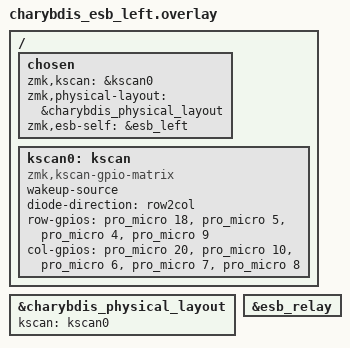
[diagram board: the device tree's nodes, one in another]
#include "charybdis_matrix.dtsi"
#include "charybdis_esb_addr.dtsi"

/ {
    chosen {
        zmk,kscan = &kscan0;
        zmk,physical-layout = &charybdis_physical_layout;
        zmk,esb-self = &esb_left;
    };

    kscan0: kscan {
        compatible = "zmk,kscan-gpio-matrix";
        wakeup-source;
        diode-direction = "row2col";
        row-gpios
            = <&pro_micro 18 GPIO_ACTIVE_HIGH>
            , <&pro_micro 5 GPIO_ACTIVE_HIGH>
            , <&pro_micro 4 GPIO_ACTIVE_HIGH>
            , <&pro_micro 9 GPIO_ACTIVE_HIGH>
            ;
        col-gpios
            = <&pro_micro 20 (GPIO_ACTIVE_HIGH | GPIO_PULL_DOWN)>
            , <&pro_micro 10 (GPIO_ACTIVE_HIGH | GPIO_PULL_DOWN)>
            , <&pro_micro 6 (GPIO_ACTIVE_HIGH | GPIO_PULL_DOWN)>
            , <&pro_micro 7 (GPIO_ACTIVE_HIGH | GPIO_PULL_DOWN)>
            , <&pro_micro 8 (GPIO_ACTIVE_HIGH | GPIO_PULL_DOWN)>
            ;
    };
};

&charybdis_physical_layout {
    kscan = <&kscan0>;
};


/* Every node must enable the same set of ESB pipes, relay included. The central
 * sizes its beacon (hop epoch, channel mask, HID state) as 4 + 2 bytes per
 * enabled pipe, and a peripheral recognizes a beacon only at the length its own
 * devicetree computes. With the relay pipe left disabled here this node expects
 * a 10-byte beacon while the right-central sends 12, so it dropped every beacon
 * ("Dropping command with unexpected size 12") and could not adopt the central's
 * hop epoch. The pipe is only used by the relay dongle; enabling it here just
 * keeps the peer table the same size everywhere. */
&esb_relay {
    status = "okay";
};
